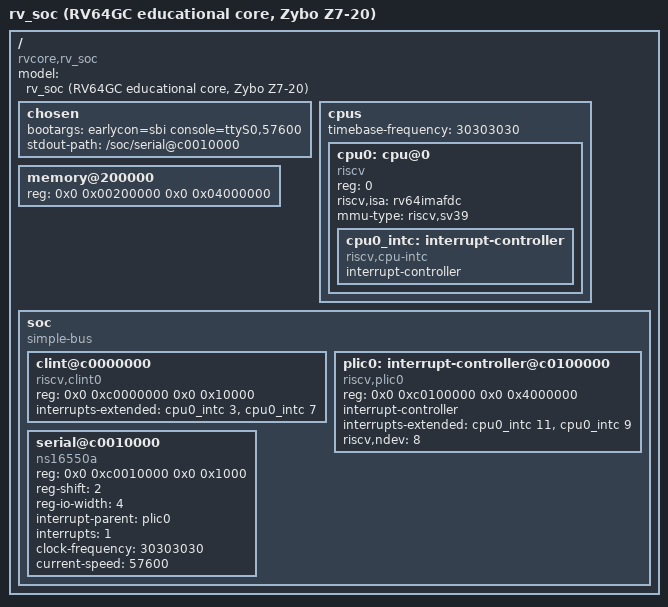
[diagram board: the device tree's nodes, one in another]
/dts-v1/;

/* Real-HARDWARE Linux device tree for the Zybo Z7-20 bitstream.
 *
 * Derived from rv_soc_linux_lo.dts (the sim-verified, base-relocated 0x0020_0000
 * copy).  IDENTICAL to rv_soc_linux_lo.dts EXCEPT for the three CLOCK constants
 * (timebase-frequency, serial clock-frequency, current-speed), which on real
 * silicon must reflect the ACTUAL PL clock rather than the sim placeholders.
 * See docs/opensbi/rv_soc_hw.dts for the full derivation; in brief, with
 * MTIME_DIV=1 the real FCLK_CLK0 = IO PLL (1000 MHz) / divisor (set by
 * build_zybo.tcl PL_FREQMHZ via PCW; ps7_init 0xF8000170):
 *
 *   - timebase-frequency / serial clock-frequency = the ACTUAL FCLK in Hz (mtime
 *       ticks at FCLK; the 8250 divisor = clock-frequency/(16*baud) and
 *       actual_baud = FCLK/(16*divisor), so both must equal the real FCLK or the
 *       wall-clock / baud come out wrong).
 *   - current-speed = console baud (the live values + the baud error are in the
 *       inline comments on each property below).
 *
 * These three constants are rewritten by boards/zybo_z720/set_pl_freq.py <MHz> on
 * a clock retarget -- do NOT hand-edit them out of sync with PL_FREQMHZ.
 *
 * The kernel Image is relocatable / base-independent; only this DTB + the OpenSBI
 * wrapper depend on the firmware base.  /memory is kept at 64 MiB for bring-up
 * parity with the sim-verified image (1 GB PS DDR is a later P2 step).
 */

/ {
    #address-cells = <2>;
    #size-cells = <2>;
    compatible = "rvcore,rv_soc";
    model = "rv_soc (RV64GC educational core, Zybo Z7-20)";

    chosen {
        bootargs = "earlycon=sbi console=ttyS0,57600";
        stdout-path = "/soc/serial@c0010000";
    };

    cpus {
        #address-cells = <1>;
        #size-cells = <0>;
        timebase-frequency = <30303030>;  /* mtime = PL/MTIME_DIV = 30.303 MHz/1 */

        cpu0: cpu@0 {
            device_type = "cpu";
            reg = <0>;
            compatible = "riscv";
            riscv,isa = "rv64imafdc";
            mmu-type = "riscv,sv39";
            status = "okay";

            cpu0_intc: interrupt-controller {
                #interrupt-cells = <1>;
                interrupt-controller;
                compatible = "riscv,cpu-intc";
            };
        };
    };

    /* 64 MiB at the re-linked base (0x0020_0000) for bring-up parity. */
    memory@200000 {
        device_type = "memory";
        reg = <0x0 0x00200000  0x0 0x04000000>;
    };

    soc {
        #address-cells = <2>;
        #size-cells = <2>;
        compatible = "simple-bus";
        ranges;

        clint@c0000000 {
            compatible = "riscv,clint0";
            reg = <0x0 0xc0000000  0x0 0x10000>;
            interrupts-extended = <&cpu0_intc 3 &cpu0_intc 7>;  /* MSIP, MTIP */
        };

        plic0: interrupt-controller@c0100000 {
            compatible = "riscv,plic0";
            reg = <0x0 0xc0100000  0x0 0x4000000>;
            #interrupt-cells = <1>;
            interrupt-controller;
            interrupts-extended = <&cpu0_intc 11 &cpu0_intc 9>; /* MEIP, SEIP */
            riscv,ndev = <8>;
        };

        serial@c0010000 {
            compatible = "ns16550a";
            reg = <0x0 0xc0010000  0x0 0x1000>;
            reg-shift = <2>;
            reg-io-width = <4>;
            interrupt-parent = <&plic0>;
            interrupts = <1>;
            clock-frequency = <30303030>;  /* = PL clock; sets the 8250 divisor */
            current-speed = <57600>;  /* 30.303e6/(16*33)=57392, -0.36% */
        };
    };
};
